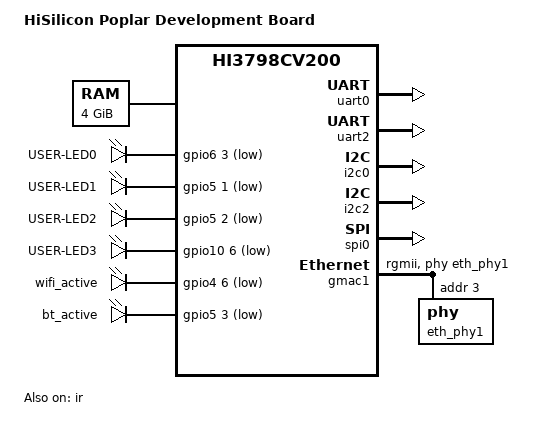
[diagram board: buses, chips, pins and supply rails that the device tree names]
/*
 * DTS File for HiSilicon Poplar Development Board
 *
 * Copyright (c) 2016-2017 HiSilicon Technologies Co., Ltd.
 *
 * Released under the GPLv2 only.
 * SPDX-License-Identifier: GPL-2.0
 */

/dts-v1/;

#include <dt-bindings/gpio/gpio.h>
#include "hi3798cv200.dtsi"
#include "poplar-pinctrl.dtsi"
/ {
	model = "HiSilicon Poplar Development Board";
	compatible = "hisilicon,hi3798cv200-poplar", "hisilicon,hi3798cv200";

	aliases {
		serial0 = &uart0;
		serial1 = &uart2;
		spi0 = &spi0;
	};

	chosen {
		stdout-path = "serial0:115200n8";
	    bootargs = "mem=2G root=/dev/mmcblk0p7 rootfstype=ext4 rootwait rw blkdevparts=mmcblk0:2M(boot),4M(baseparam),4M(pqparam),\
				4M(logo),88M(trustedcore),32M(kernel),256M(rootfs),-(others) earlycon";
	};

	memory@0 {
		device_type = "memory";
		reg = <0x000000000 0x00000000 0x00000001 0x00000000>;
	};
	
	soc {
	
	    uart0: uart@f8b00000 {
			status = "ok";
		};

		uart2: uart@f8b02000 {
			status = "ok";
		};

		i2c0: i2c@f8b10000 {
			status = "ok";
		};

		i2c2: i2c@f8b12000 {
			status = "ok";
		};

		spi0: spi@f8b1a000 {
			status = "ok";
		};

	    leds {
	     	compatible = "gpio-leds";

		    user-led0 {
		     	label = "USER-LED0";
			    gpios = <&gpio6 3 GPIO_ACTIVE_LOW>;
		    	linux,default-trigger = "heartbeat";
		    	default-state = "off";
		    };

		    user-led1 {
		    	label = "USER-LED1";
		    	gpios = <&gpio5 1 GPIO_ACTIVE_LOW>;
		    	linux,default-trigger = "mmc0";
		    	default-state = "off";
		    };

		    user-led2 {
		    	label = "USER-LED2";
		    	gpios = <&gpio5 2 GPIO_ACTIVE_LOW>;
		    	linux,default-trigger = "none";
		    	default-state = "off";
		    };

		    user-led3 {
		    	label = "USER-LED3";
		    	gpios = <&gpio10 6 GPIO_ACTIVE_LOW>;
		    	linux,default-trigger = "cpu0";
		    	default-state = "off";
		    };

		    wlan_active_led {
		    	label = "wifi_active";
		    	gpios = <&gpio4 6 GPIO_ACTIVE_LOW>;
		    	linux,default-trigger = "wlan";
		    	default-state = "off";
		    };

		    bt_active_led {
		    	label = "bt_active";
		    	gpios = <&gpio5 3 GPIO_ACTIVE_LOW>;
		    	linux,default-trigger = "bt";
		    	default-state = "off";
		    };
		};
	};
};

&gmac1 {
	status = "okay";
	#address-cells = <1>;
	#size-cells = <0>;
	phy-handle = <&eth_phy1>;
	phy-mode = "rgmii";
	hisilicon,phy-reset-delays-us = <10000 10000 30000>;

	eth_phy1: phy@3 {
		reg = <3>;
	};
};

&gpio1 {
	status = "okay";
	gpio-line-names = "LS-GPIO-E",	"",
			  "",		"",
			  "",		"LS-GPIO-F",
			  "",		"LS-GPIO-J";
};

&gpio2 {
	status = "okay";
	gpio-line-names = "LS-GPIO-H",	"LS-GPIO-I",
			  "LS-GPIO-L",	"LS-GPIO-G",
			  "LS-GPIO-K",	"",
			  "",		"";
};

&gpio3 {
	status = "okay";
	gpio-line-names = "",		"",
			  "",		"",
			  "LS-GPIO-C",	"",
			  "",		"LS-GPIO-B";
};

&gpio4 {
	status = "okay";
	gpio-line-names = "",		"",
			  "",		"",
			  "",		"LS-GPIO-D",
			  "",		"";
};

&gpio5 {
	status = "okay";
	gpio-line-names = "",		"USER-LED-1",
			  "USER-LED-2",	"",
			  "",		"LS-GPIO-A",
			  "",		"";
};

&gpio6 {
	status = "okay";
	gpio-line-names = "",		"",
			  "",		"USER-LED-0",
			  "",		"",
			  "",		"";
};

&gpio10 {
	status = "okay";
	gpio-line-names = "",		"",
			  "",		"",
			  "",		"",
			  "USER-LED-3",	"";
};


&ir {
	status = "okay";
};

/* No optional LS-UART1 on Low Speed Expansion Connector. */
